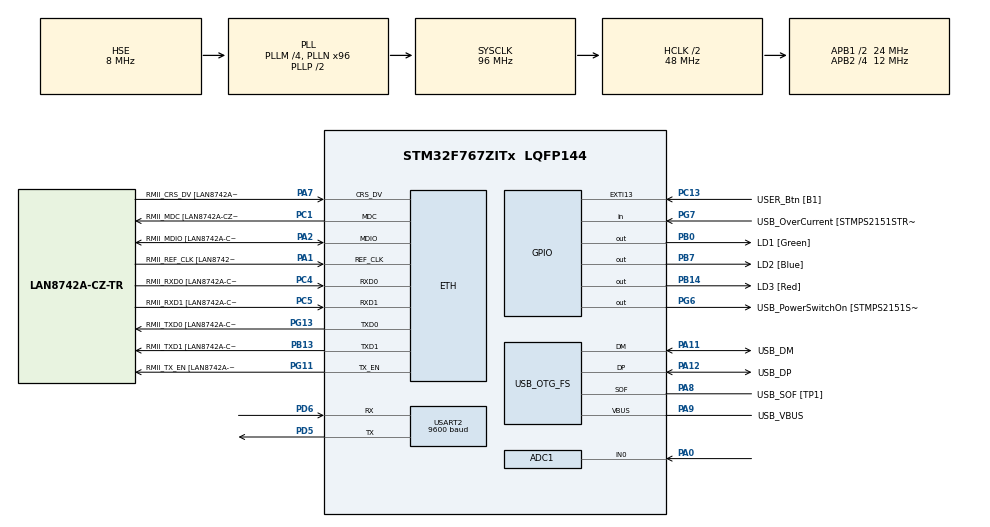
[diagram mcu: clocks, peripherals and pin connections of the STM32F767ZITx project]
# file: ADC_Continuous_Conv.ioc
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ADC1.Channel-0\#ChannelRegularConversion=ADC_CHANNEL_0
ADC1.ClockPrescaler=ADC_CLOCK_SYNC_PCLK_DIV6
ADC1.ContinuousConvMode=ENABLE
ADC1.ExternalTrigConv=ADC_SOFTWARE_START
ADC1.InjNumberOfConversion=0
ADC1.NbrOfConversion=1
ADC1.NbrOfConversionFlag=1
ADC1.Rank-0\#ChannelRegularConversion=1
ADC1.Resolution=ADC_RESOLUTION_8B
ADC1.SamplingTime-0\#ChannelRegularConversion=ADC_SAMPLETIME_480CYCLES
ADC1.ScanConvMode=ADC_SCAN_DISABLE
ADC1.master=1
ETH.MediaInterface=ETH_MEDIA_INTERFACE_RMII
ETH.PHY_Name=LAN8742A_PHY_ADDRESS
ETH.PHY_Value=0
ETH.PhyAddress=0
Mcu.Family=STM32F7
Mcu.Name=STM32F767ZITx
Mcu.Package=LQFP144
NVIC.PriorityGroup=NVIC_PRIORITYGROUP_4
NVIC.USART2_IRQn=true\:0\:0\:false\:false\:true\:true\:true
PA0/WKUP.Signal=ADCx_IN0
PA1.GPIO_Label=RMII_REF_CLK [LAN8742A-CZ-TR_REFCLK0]
PA1.Mode=RMII
PA1.Signal=ETH_REF_CLK
PA10.GPIO_Label=USB_ID
PA10.Signal=USB_OTG_FS_ID
PA11.GPIO_Label=USB_DM
PA11.Mode=Device_Only
PA11.Signal=USB_OTG_FS_DM
PA12.GPIO_Label=USB_DP
PA12.Mode=Device_Only
PA12.Signal=USB_OTG_FS_DP
PA13.GPIO_Label=TMS
PA13.Mode=Serial_Wire
PA13.Signal=SYS_JTMS-SWDIO
PA14.GPIO_Label=TCK
PA14.Mode=Serial_Wire
PA14.Signal=SYS_JTCK-SWCLK
PA2.GPIO_Label=RMII_MDIO [LAN8742A-CZ-TR_MDIO]
PA2.Mode=RMII
PA2.Signal=ETH_MDIO
PA7.GPIO_Label=RMII_CRS_DV [LAN8742A-CZ-TR_CRS_DV]
PA7.Mode=RMII
PA7.Signal=ETH_CRS_DV
PA8.GPIO_Label=USB_SOF [TP1]
PA8.Mode=Activate_SOF_FS
PA8.Signal=USB_OTG_FS_SOF
PA9.GPIO_Label=USB_VBUS
PA9.Mode=Activate_VBUS
PA9.Signal=USB_OTG_FS_VBUS
PB0.GPIO_Label=LD1 [Green]
PB0.Signal=GPIO_Output
PB13.GPIO_Label=RMII_TXD1 [LAN8742A-CZ-TR_TXD1]
PB13.Mode=RMII
PB13.Signal=ETH_TXD1
PB14.GPIO_Label=LD3 [Red]
PB14.Signal=GPIO_Output
PB3.GPIO_Label=SWO
PB3.Signal=SYS_JTDO-SWO
PB7.GPIO_Label=LD2 [Blue]
PB7.Signal=GPIO_Output
PC1.GPIO_Label=RMII_MDC [LAN8742A-CZ-TR_MDC]
PC1.Mode=RMII
PC1.Signal=ETH_MDC
PC13.GPIO_Label=USER_Btn [B1]
PC13.Signal=GPXTI13
PC14/OSC32_IN.Mode=LSE-External-Oscillator
PC14/OSC32_IN.Signal=RCC_OSC32_IN
PC15/OSC32_OUT.Mode=LSE-External-Oscillator
PC15/OSC32_OUT.Signal=RCC_OSC32_OUT
PC4.GPIO_Label=RMII_RXD0 [LAN8742A-CZ-TR_RXD0]
PC4.Mode=RMII
PC4.Signal=ETH_RXD0
PC5.GPIO_Label=RMII_RXD1 [LAN8742A-CZ-TR_RXD1]
PC5.Mode=RMII
PC5.Signal=ETH_RXD1
PD5.Mode=Asynchronous
PD5.Signal=USART2_TX
PD6.Mode=Asynchronous
PD6.Signal=USART2_RX
PD8.GPIO_Label=STLK_RX [STM32F103CBT6_PA3]
PD8.Signal=USART3_TX
PD9.GPIO_Label=STLK_TX [STM32F103CBT6_PA2]
PD9.Signal=USART3_RX
PG11.GPIO_Label=RMII_TX_EN [LAN8742A-CZ-TR_TXEN]
PG11.Mode=RMII
PG11.Signal=ETH_TX_EN
PG13.GPIO_Label=RMII_TXD0 [LAN8742A-CZ-TR_TXD0]
PG13.Mode=RMII
PG13.Signal=ETH_TXD0
PG6.GPIO_Label=USB_PowerSwitchOn [STMPS2151STR_EN]
PG6.Signal=GPIO_Output
PG7.GPIO_Label=USB_OverCurrent [STMPS2151STR_FAULT]
PG7.Signal=GPIO_Input
PH0/OSC_IN.GPIO_Label=MCO [STM32F103CBT6_PA8]
PH0/OSC_IN.Mode=HSE-External-Clock-Source
PH0/OSC_IN.Signal=RCC_OSC_IN
PH1/OSC_OUT.Mode=HSE-External-Clock-Source
PH1/OSC_OUT.Signal=RCC_OSC_OUT
ProjectManager.HeapSize=0x200
ProjectManager.StackSize=0x400
ProjectManager.TargetToolchain=TrueSTUDIO
RCC.48MHZClocksFreq_Value=24000000
RCC.AHBCLKDivider=RCC_SYSCLK_DIV2
RCC.AHBFreq_Value=48000000
RCC.APB1CLKDivider=RCC_HCLK_DIV2
RCC.APB1Freq_Value=24000000
RCC.APB1TimFreq_Value=48000000
RCC.APB2CLKDivider=RCC_HCLK_DIV4
RCC.APB2Freq_Value=12000000
RCC.APB2TimFreq_Value=24000000
RCC.CortexFreq_Value=48000000
RCC.HCLKFreq_Value=48000000
RCC.HSE_VALUE=8000000
RCC.HSI_VALUE=16000000
RCC.PLLM=4
RCC.PLLMUL=RCC_PLL_MUL9
RCC.PLLN=96
RCC.PLLQ=4
RCC.PRESCALERUSB=RCC_USBCLKSOURCE_PLL_DIV1_5
RCC.SYSCLKFreq_VALUE=96000000
RCC.SYSCLKSource=RCC_SYSCLKSOURCE_PLLCLK
RCC.SYSCLKSourceVirtual=RCC_SYSCLKSOURCE_PLLCLK
RCC.USBFreq_Value=48000000
RCC.VCOOutputFreq_Value=192000000
SH.ADCx_IN0.0=ADC1_IN0,IN0
USART2.BaudRate=9600
USART2.Mode=MODE_TX_RX
USART2.VirtualMode-Asynchronous=VM_ASYNC
USB_OTG_FS.VirtualMode=Device_Only
board=NUCLEO-F767ZI

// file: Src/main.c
/* USER CODE BEGIN Header */
/**
  ******************************************************************************
  * @file           : main.c
  * @brief          : Main program body
  ******************************************************************************
  * @attention
  *
  * <h2><center>&copy; Copyright (c) 2019 STMicroelectronics.
  * All rights reserved.</center></h2>
  *
  * This software component is licensed by ST under BSD 3-Clause license,
  * the "License"; You may not use this file except in compliance with the
  * License. You may obtain a copy of the License at:
  *                        opensource.org/licenses/BSD-3-Clause
  *
  ******************************************************************************
  */
/* USER CODE END Header */

#include "main.h"

ADC_HandleTypeDef hadc1;

ETH_HandleTypeDef heth;

UART_HandleTypeDef huart2;

PCD_HandleTypeDef hpcd_USB_OTG_FS;

void SystemClock_Config(void);
static void MX_GPIO_Init(void);
static void MX_ETH_Init(void);
static void MX_USB_OTG_FS_PCD_Init(void);
static void MX_ADC1_Init(void);
static void MX_USART2_UART_Init(void);

/* USER CODE BEGIN 0 */
uint8_t n8Value;
/* USER CODE END 0 */

int main(void)
{

  /* MCU Configuration--------------------------------------------------------*/

  /* Reset of all peripherals, Initializes the Flash interface and the Systick. */
  HAL_Init();

  /* Configure the system clock */
  SystemClock_Config();

  /* Initialize all configured peripherals */
  MX_GPIO_Init();
  MX_ETH_Init();
  MX_USB_OTG_FS_PCD_Init();
  MX_ADC1_Init();
  MX_USART2_UART_Init();

  /* Infinite loop */
  while (1)
  {

    /* USER CODE BEGIN 3 */
	  HAL_ADC_Start(&hadc1);

	  n8Value = HAL_ADC_GetValue(&hadc1);

	  HAL_UART_Transmit(&huart2,&n8Value,sizeof(n8Value),1000);

	  HAL_Delay(500);
  }
  /* USER CODE END 3 */
}

void SystemClock_Config(void)
{
  RCC_OscInitTypeDef RCC_OscInitStruct = {0};
  RCC_ClkInitTypeDef RCC_ClkInitStruct = {0};
  RCC_PeriphCLKInitTypeDef PeriphClkInitStruct = {0};

  /** Configure LSE Drive Capability
  */
  HAL_PWR_EnableBkUpAccess();
  /** Configure the main internal regulator output voltage
  */
  __HAL_RCC_PWR_CLK_ENABLE();
  __HAL_PWR_VOLTAGESCALING_CONFIG(PWR_REGULATOR_VOLTAGE_SCALE3);
  /** Initializes the CPU, AHB and APB busses clocks
  */
  RCC_OscInitStruct.OscillatorType = RCC_OSCILLATORTYPE_HSE;
  RCC_OscInitStruct.HSEState = RCC_HSE_BYPASS;
  RCC_OscInitStruct.PLL.PLLState = RCC_PLL_ON;
  RCC_OscInitStruct.PLL.PLLSource = RCC_PLLSOURCE_HSE;
  RCC_OscInitStruct.PLL.PLLM = 4;
  RCC_OscInitStruct.PLL.PLLN = 96;
  RCC_OscInitStruct.PLL.PLLP = RCC_PLLP_DIV2;
  RCC_OscInitStruct.PLL.PLLQ = 4;
  if (HAL_RCC_OscConfig(&RCC_OscInitStruct) != HAL_OK)
  {
    Error_Handler();
  }
  /** Initializes the CPU, AHB and APB busses clocks
  */
  RCC_ClkInitStruct.ClockType = RCC_CLOCKTYPE_HCLK|RCC_CLOCKTYPE_SYSCLK
                              |RCC_CLOCKTYPE_PCLK1|RCC_CLOCKTYPE_PCLK2;
  RCC_ClkInitStruct.SYSCLKSource = RCC_SYSCLKSOURCE_PLLCLK;
  RCC_ClkInitStruct.AHBCLKDivider = RCC_SYSCLK_DIV2;
  RCC_ClkInitStruct.APB1CLKDivider = RCC_HCLK_DIV2;
  RCC_ClkInitStruct.APB2CLKDivider = RCC_HCLK_DIV4;

  if (HAL_RCC_ClockConfig(&RCC_ClkInitStruct, FLASH_LATENCY_1) != HAL_OK)
  {
    Error_Handler();
  }
  PeriphClkInitStruct.PeriphClockSelection = RCC_PERIPHCLK_USART2|RCC_PERIPHCLK_CLK48;
  PeriphClkInitStruct.Usart2ClockSelection = RCC_USART2CLKSOURCE_PCLK1;
  PeriphClkInitStruct.Clk48ClockSelection = RCC_CLK48SOURCE_PLL;
  if (HAL_RCCEx_PeriphCLKConfig(&PeriphClkInitStruct) != HAL_OK)
  {
    Error_Handler();
  }
}

static void MX_ADC1_Init(void)
{

  ADC_ChannelConfTypeDef sConfig = {0};

  /** Configure the global features of the ADC (Clock, Resolution, Data Alignment and number of conversion)
  */
  hadc1.Instance = ADC1;
  hadc1.Init.ClockPrescaler = ADC_CLOCK_SYNC_PCLK_DIV6;
  hadc1.Init.Resolution = ADC_RESOLUTION_8B;
  hadc1.Init.ScanConvMode = ADC_SCAN_DISABLE;
  hadc1.Init.ContinuousConvMode = ENABLE;
  hadc1.Init.DiscontinuousConvMode = DISABLE;
  hadc1.Init.ExternalTrigConvEdge = ADC_EXTERNALTRIGCONVEDGE_NONE;
  hadc1.Init.ExternalTrigConv = ADC_SOFTWARE_START;
  hadc1.Init.DataAlign = ADC_DATAALIGN_RIGHT;
  hadc1.Init.NbrOfConversion = 1;
  hadc1.Init.DMAContinuousRequests = DISABLE;
  hadc1.Init.EOCSelection = ADC_EOC_SINGLE_CONV;
  if (HAL_ADC_Init(&hadc1) != HAL_OK)
  {
    Error_Handler();
  }
  /** Configure for the selected ADC regular channel its corresponding rank in the sequencer and its sample time.
  */
  sConfig.Channel = ADC_CHANNEL_0;
  sConfig.Rank = ADC_REGULAR_RANK_1;
  sConfig.SamplingTime = ADC_SAMPLETIME_480CYCLES;
  if (HAL_ADC_ConfigChannel(&hadc1, &sConfig) != HAL_OK)
  {
    Error_Handler();
  }

}

static void MX_ETH_Init(void)
{

  heth.Instance = ETH;
  heth.Init.AutoNegotiation = ETH_AUTONEGOTIATION_ENABLE;
  heth.Init.PhyAddress = LAN8742A_PHY_ADDRESS;
  heth.Init.MACAddr[0] =   0x00;
  heth.Init.MACAddr[1] =   0x80;
  heth.Init.MACAddr[2] =   0xE1;
  heth.Init.MACAddr[3] =   0x00;
  heth.Init.MACAddr[4] =   0x00;
  heth.Init.MACAddr[5] =   0x00;
  heth.Init.RxMode = ETH_RXPOLLING_MODE;
  heth.Init.ChecksumMode = ETH_CHECKSUM_BY_HARDWARE;
  heth.Init.MediaInterface = ETH_MEDIA_INTERFACE_RMII;

  if (HAL_ETH_Init(&heth) != HAL_OK)
  {
    Error_Handler();
  }

}

static void MX_USART2_UART_Init(void)
{

  huart2.Instance = USART2;
  huart2.Init.BaudRate = 9600;
  huart2.Init.WordLength = UART_WORDLENGTH_8B;
  huart2.Init.StopBits = UART_STOPBITS_1;
  huart2.Init.Parity = UART_PARITY_NONE;
  huart2.Init.Mode = UART_MODE_TX_RX;
  huart2.Init.HwFlowCtl = UART_HWCONTROL_NONE;
  huart2.Init.OverSampling = UART_OVERSAMPLING_16;
  huart2.Init.OneBitSampling = UART_ONE_BIT_SAMPLE_DISABLE;
  huart2.AdvancedInit.AdvFeatureInit = UART_ADVFEATURE_NO_INIT;
  if (HAL_UART_Init(&huart2) != HAL_OK)
  {
    Error_Handler();
  }

}

static void MX_USB_OTG_FS_PCD_Init(void)
{

  hpcd_USB_OTG_FS.Instance = USB_OTG_FS;
  hpcd_USB_OTG_FS.Init.dev_endpoints = 6;
  hpcd_USB_OTG_FS.Init.speed = PCD_SPEED_FULL;
  hpcd_USB_OTG_FS.Init.dma_enable = DISABLE;
  hpcd_USB_OTG_FS.Init.phy_itface = PCD_PHY_EMBEDDED;
  hpcd_USB_OTG_FS.Init.Sof_enable = ENABLE;
  hpcd_USB_OTG_FS.Init.low_power_enable = DISABLE;
  hpcd_USB_OTG_FS.Init.lpm_enable = DISABLE;
  hpcd_USB_OTG_FS.Init.vbus_sensing_enable = ENABLE;
  hpcd_USB_OTG_FS.Init.use_dedicated_ep1 = DISABLE;
  if (HAL_PCD_Init(&hpcd_USB_OTG_FS) != HAL_OK)
  {
    Error_Handler();
  }

}

static void MX_GPIO_Init(void)
{
  GPIO_InitTypeDef GPIO_InitStruct = {0};

  /* GPIO Ports Clock Enable */
  __HAL_RCC_GPIOC_CLK_ENABLE();
  __HAL_RCC_GPIOH_CLK_ENABLE();
  __HAL_RCC_GPIOA_CLK_ENABLE();
  __HAL_RCC_GPIOB_CLK_ENABLE();
  __HAL_RCC_GPIOD_CLK_ENABLE();
  __HAL_RCC_GPIOG_CLK_ENABLE();

  /*Configure GPIO pin Output Level */
  HAL_GPIO_WritePin(GPIOB, LD1_Pin|LD3_Pin|LD2_Pin, GPIO_PIN_RESET);

  /*Configure GPIO pin Output Level */
  HAL_GPIO_WritePin(USB_PowerSwitchOn_GPIO_Port, USB_PowerSwitchOn_Pin, GPIO_PIN_RESET);

  /*Configure GPIO pin : USER_Btn_Pin */
  GPIO_InitStruct.Pin = USER_Btn_Pin;
  GPIO_InitStruct.Mode = GPIO_MODE_IT_RISING;
  GPIO_InitStruct.Pull = GPIO_NOPULL;
  HAL_GPIO_Init(USER_Btn_GPIO_Port, &GPIO_InitStruct);

  /*Configure GPIO pins : LD1_Pin LD3_Pin LD2_Pin */
  GPIO_InitStruct.Pin = LD1_Pin|LD3_Pin|LD2_Pin;
  GPIO_InitStruct.Mode = GPIO_MODE_OUTPUT_PP;
  GPIO_InitStruct.Pull = GPIO_NOPULL;
  GPIO_InitStruct.Speed = GPIO_SPEED_FREQ_LOW;
  HAL_GPIO_Init(GPIOB, &GPIO_InitStruct);

  /*Configure GPIO pins : STLK_RX_Pin STLK_TX_Pin */
  GPIO_InitStruct.Pin = STLK_RX_Pin|STLK_TX_Pin;
  GPIO_InitStruct.Mode = GPIO_MODE_AF_PP;
  GPIO_InitStruct.Pull = GPIO_NOPULL;
  GPIO_InitStruct.Speed = GPIO_SPEED_FREQ_VERY_HIGH;
  GPIO_InitStruct.Alternate = GPIO_AF7_USART3;
  HAL_GPIO_Init(GPIOD, &GPIO_InitStruct);

  /*Configure GPIO pin : USB_PowerSwitchOn_Pin */
  GPIO_InitStruct.Pin = USB_PowerSwitchOn_Pin;
  GPIO_InitStruct.Mode = GPIO_MODE_OUTPUT_PP;
  GPIO_InitStruct.Pull = GPIO_NOPULL;
  GPIO_InitStruct.Speed = GPIO_SPEED_FREQ_LOW;
  HAL_GPIO_Init(USB_PowerSwitchOn_GPIO_Port, &GPIO_InitStruct);

  /*Configure GPIO pin : USB_OverCurrent_Pin */
  GPIO_InitStruct.Pin = USB_OverCurrent_Pin;
  GPIO_InitStruct.Mode = GPIO_MODE_INPUT;
  GPIO_InitStruct.Pull = GPIO_NOPULL;
  HAL_GPIO_Init(USB_OverCurrent_GPIO_Port, &GPIO_InitStruct);

}

void Error_Handler(void)
{
}

/************************ (C) COPYRIGHT STMicroelectronics *****END OF FILE****/
